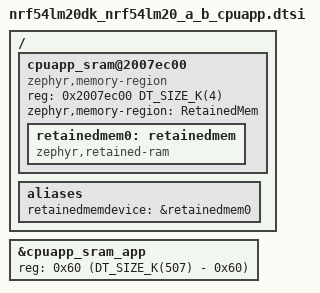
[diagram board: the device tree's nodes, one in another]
/ {
	cpuapp_sram@2007ec00 {
		compatible = "zephyr,memory-region", "mmio-sram";
		reg = <0x2007ec00 DT_SIZE_K(4)>;
		zephyr,memory-region = "RetainedMem";
		status = "okay";

		retainedmem0: retainedmem {
			compatible = "zephyr,retained-ram";
			status = "okay";
		};
	};

	aliases {
		retainedmemdevice = &retainedmem0;
	};
};

&cpuapp_sram_app {
	/* Shrink SRAM size to avoid overlap with retained memory region:
	 * 511 - 4 = 507KB = 0x7ec00
	 */
	reg = <0x60 (DT_SIZE_K(507) - 0x60)>;
};
